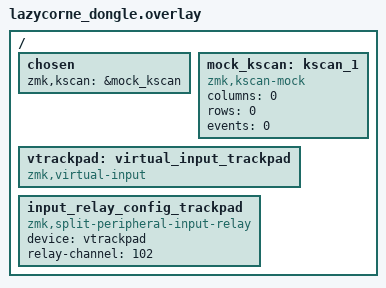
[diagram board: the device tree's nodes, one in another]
#include "lazycorne.dtsi"

/ {
    chosen {
        zmk,kscan = &mock_kscan;
    };

    mock_kscan: kscan_1 {
        compatible = "zmk,kscan-mock";
        columns = <0>;
        rows = <0>;
        events = <0>;
    };
};

/ {
  vtrackpad: virtual_input_trackpad {
    compatible = "zmk,virtual-input";
  };

  input_relay_config_trackpad {
    compatible = "zmk,split-peripheral-input-relay";
    device = <&vtrackpad>;
    relay-channel = <102>;
  };
};
